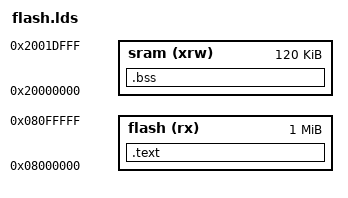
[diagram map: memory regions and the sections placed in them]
/* flash.lds
 * linker script for stm32f207
 *
 * Memory layout on STM32F207:
 *
 * 0xA000 0000 - 0xA000 0FFF - FSMC control register 
 * 0x5006 0800 - 0X5006 0BFF - RNG
 * 0x5006 0400 - 0X5006 07FF - HASH 
 * 0x5006 0000 - 0X5006 03FF - CRYP
 * 0x5000 0000 - 0X5003 FFFF - USB OTG FS
 * 0x4004 0000 - 0x4007 FFFF - USB OTG HS
 * 0x4002 9000 - 0x4002 93FF - ETHERNET MAC
 * 0x4002 8C00 - 0x4002 8FFF -
 * 0x4002 8800 - 0x4002 8BFF -
 * 0x4002 8400 - 0x4002 87FF -
 * 0x4002 8000 - 0x4002 83FF -
 * 0x4002 6400 - 0x4002 67FF - DMA2
 * 0x4002 6000 - 0x4002 63FF - DMA1
 * 0x4002 4000 - 0x4002 4FFF - BKPSRAM
 * 0x4002 3C00 - 0x4002 3FFF - Flash interface register
 * 0x4002 3800 - 0x4002 3BFF - RCC
 * 0x4002 3000 - 0x4002 33FF - CRC
 * 0x4002 2000 - 0x4002 23FF - GPIOI
 * 0x4002 1C00 - 0x4002 1FFF - GPIOH
 * 0x4002 1800 - 0x4002 1BFF - GPIOG
 * 0x4002 1400 - 0x4002 17FF - GPIOF
 * 0X4002 0C00 - 0x4002 0FFF - GPIOD
 * 0x4002 0800 - 0x4002 0BFF - GPIOC
 * 0x4002 0400 - 0x4002 07FF - GPIOB
 * 0x4002 0000 - 0x4002 03FF - GPIOA
 * 0x4001 4800 - 0x4001 4BFF - TIM11
 * 0x4001 4400 - 0x4001 47FF - TIM10
 * 0x4001 4000 - 0x4001 43FF - TIM9 
 * 0x4001 3C00 - 0x4001 3FFF - EXTI
 * 0x4001 3800 - 0x4001 3BFF - SYSCFG
 * 0x4001 3000 - 0x4001 33FF - SPI1 
 * 0x4001 2C00 - 0x4001 2FFF - SDIO
 * 0x4001 2000 - 0x4001 23FF - ADC1 - ADC2 - ADC3
 * 0x4001 1400 - 0x4001 17FF - USART6 
 * 0x4001 1000 - 0x4001 13FF - USART1
 * 0x4001 0400 - 0x4001 07FF - TIM8
 * 0x4001 0000 - 0x4001 03FF - TIM1
 * 0x4000 7400 - 0x4000 77FF - DAC
 * 0x4000 7000 - 0x4000 73FF - PWR
 * 0x4000 6800 - 0x4000 6BFF - CAN2
 * 0x4000 6400 - 0x4000 67FF - CAN1
 * 0x4000 5C00 - 0x4000 5FFF - I2C3
 * 0x4000 5800 - 0x4000 5BFF - I2C2
 * 0x4000 5400 - 0x4000 57FF - I2C1
 * 0x4000 5000 - 0x4000 53FF - UART5
 * 0x4000 4C00 - 0x4000 4FFF - UART4
 * 0x4000 4800 - 0x4000 4BFF - USART3
 * 0x4000 4400 - 0x4000 47FF - USART2
 * 0x4000 3C00 - 0x4000 3FFF - SPI3 / I2S3
 * 0x4000 3800 - 0x4000 3BFF - SPI2 / I2S2
 * 0x4000 3000 - 0x4000 33FF - IWDG
 * 0x4000 2C00 - 0x4000 2FFF - WWDG
 * 0x4000 2800 - 0x4000 2BFF - RTC & BKP Registers
 * 0x4000 2000 - 0x4000 23FF - TIM14
 * 0x4000 1C00 - 0x4000 1FFF - TIM13
 * 0x4000 1800 - 0x4000 1BFF - TIM12
 * 0x4000 1400 - 0x4000 17FF - TIM7 
 * 0x4000 1000 - 0x4000 13FF - TIM6
 * 0x4000 0C00 - 0x4000 0FFF - TIM5
 * 0x4000 0800 - 0x4000 0BFF - TIM4
 * 0x4000 0400 - 0x4000 07FF - TIM3
 * 0x4000 0000 - 0x4000 03FF - TIM2
 *
 * Main memory
 *
 * Sector 0 0x0800 0000 - 0x0800 3FFF        - 16 Kbyte
 * Sector 1 0x0800 4000 - 0x0800 7FFF        - 16 Kbyte
 * Sector 2 0x0800 8000 - 0x0800 BFFF        - 16 Kbyte
 * Sector 3 0x0800 C000 - 0x0800 FFFF        - 16 Kbyte
 * Sector 4 0x0801 0000 - 0x0801 FFFF        - 64 Kbyte
 * Sector 5 0x0802 0000 - 0x0803 FFFF        - 128 Kbyte
 * Sector 6 0x0804 0000 - 0x0805 FFFF        - 128 Kbyte
   ***************** Sector 7-10 ***         - 128 Kbyte
 * Sector 11 0x080E 0000 - 0x080F FFFF       - 128 Kbyte
 *
 * System memory - 0x1FFF 0000 - 0x1FFF 77FF - 30 Kbyte
 * OTP           - 0x1FFF 7800 - 0x1FFF 7A0F - 528 bytes
 * Option bytes  - 0x1FFF C000 - 0x1FFF C00F - 16 bytes
 *
 */
MEMORY
{
   flash(rx)  : ORIGIN = 0x08000000, LENGTH = 1024K
   sram(xrw) : ORIGIN = 0x20000000, LENGTH = 120K
}

SECTIONS
{
   .text : { *(.text*) } > flash
   .bss  : { *(.bss*) } > sram
}
